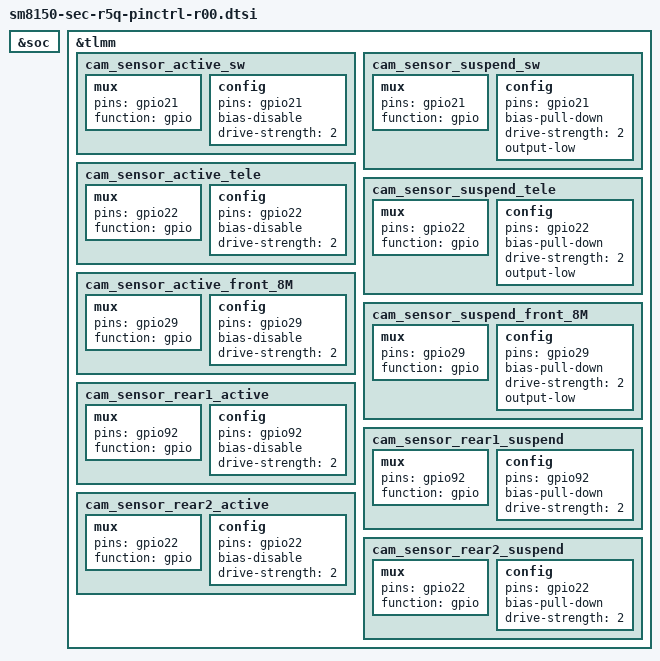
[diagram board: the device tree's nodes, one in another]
/* Copyright (c) 2016-2017, The Linux Foundation. All rights reserved.
 *
 * This program is free software; you can redistribute it and/or modify
 * it under the terms of the GNU General Public License version 2 and
 * only version 2 as published by the Free Software Foundation.
 *
 * This program is distributed in the hope that it will be useful,
 * but WITHOUT ANY WARRANTY; without even the implied warranty of
 * MERCHANTABILITY or FITNESS FOR A PARTICULAR PURPOSE.  See the
 * GNU General Public License for more details.
 */

#include "sm8150-sec-r5q-pinctrl-common.dtsi"

&soc {
	/* tlmm: pinctrl@03400000 { }; */
};

&tlmm {
	cam_sensor_active_sw: cam_sensor_active_sw {
		/* RESET SW */
		mux {
			pins = "gpio21";
			function = "gpio";
		};

		config {
			pins = "gpio21";
			bias-disable; /* No PULL */
			drive-strength = <2>; /* 2 MA */
		};
	};

	cam_sensor_suspend_sw: cam_sensor_suspend_sw {
		/* RESET SW */
		mux {
			pins = "gpio21";
			function = "gpio";
		};

		config {
			pins = "gpio21";
			bias-pull-down; /* PULL DOWN */
			drive-strength = <2>; /* 2 MA */
			output-low;
		};
	};

	cam_sensor_active_tele: cam_sensor_active_tele {
		/* RESET TELE */
		mux {
			pins = "gpio22";
			function = "gpio";
		};

		config {
			pins = "gpio22";
			bias-disable; /* No PULL */
			drive-strength = <2>; /* 2 MA */
		};
	};

	cam_sensor_suspend_tele: cam_sensor_suspend_tele {
		/* RESET TELE */
		mux {
			pins = "gpio22";
			function = "gpio";
		};

		config {
			pins = "gpio22";
			bias-pull-down; /* PULL DOWN */
			drive-strength = <2>; /* 2 MA */
			output-low;
		};
	};

	cam_sensor_active_front_8M: cam_sensor_active_front_8M {
		/* RESET FRONT 8M */
		mux {
			pins = "gpio29";
			function = "gpio";
		};

		config {
			pins = "gpio29";
			bias-disable; /* No PULL */
			drive-strength = <2>; /* 2 MA */
		};
	};

	cam_sensor_suspend_front_8M: cam_sensor_suspend_front_8M {
		/* RESET FRONT 8M */
		mux {
			pins = "gpio29";
			function = "gpio";
		};

		config {
			pins = "gpio29";
			bias-pull-down; /* PULL DOWN */
			drive-strength = <2>; /* 2 MA */
			output-low;
		};
	};
        cam_sensor_rear1_active: cam_sensor_rear1_active {
                /* RESET REAR1 */
                mux {
                        pins = "gpio92";
                        function = "gpio";
                };
                config {
                        pins = "gpio92";
                        bias-disable; /* No PULL */
                        drive-strength = <2>; /* 2 MA */
                };
        };

        cam_sensor_rear1_suspend: cam_sensor_rear1_suspend {
                /* REAR1 RESET */
                mux {
                        pins = "gpio92";
                        function = "gpio";
                };
                config {
                        pins = "gpio92";
                        bias-pull-down; /* PULL DOWN */
                        drive-strength = <2>; /* 2 MA */
                };
        };
        cam_sensor_rear2_active: cam_sensor_rear2_active {
                /* RESET REAR1 */
                mux {
                        pins = "gpio22";
                        function = "gpio";
                };
                config {
                        pins = "gpio22";
                        bias-disable; /* No PULL */
                        drive-strength = <2>; /* 2 MA */
                };
        };

        cam_sensor_rear2_suspend: cam_sensor_rear2_suspend {
                /* REAR1 RESET */
                mux {
                        pins = "gpio22";
                        function = "gpio";
                };
                config {
                        pins = "gpio22";
                        bias-pull-down; /* PULL DOWN */
                        drive-strength = <2>; /* 2 MA */
                };
        };

};
